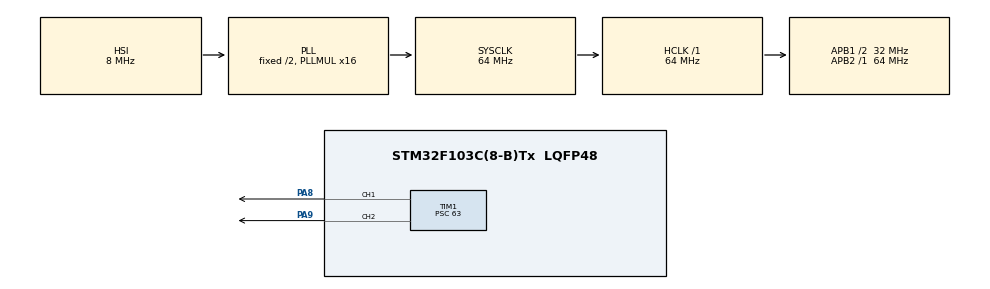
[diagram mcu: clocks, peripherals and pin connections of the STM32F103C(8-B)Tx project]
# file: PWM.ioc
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Mcu.Family=STM32F1
Mcu.Name=STM32F103C(8-B)Tx
Mcu.Package=LQFP48
NVIC.PriorityGroup=NVIC_PRIORITYGROUP_4
PA13.Mode=Serial_Wire
PA13.Signal=SYS_JTMS-SWDIO
PA14.Mode=Serial_Wire
PA14.Signal=SYS_JTCK-SWCLK
PA8.Signal=S_TIM1_CH1
PA9.Signal=S_TIM1_CH2
PD0-OSC_IN.Mode=HSE-External-Oscillator
PD0-OSC_IN.Signal=RCC_OSC_IN
PD1-OSC_OUT.Mode=HSE-External-Oscillator
PD1-OSC_OUT.Signal=RCC_OSC_OUT
ProjectManager.HeapSize=0x200
ProjectManager.StackSize=0x400
ProjectManager.TargetToolchain=MDK-ARM V5.32
RCC.AHBFreq_Value=64000000
RCC.APB1CLKDivider=RCC_HCLK_DIV2
RCC.APB1Freq_Value=32000000
RCC.APB1TimFreq_Value=64000000
RCC.APB2Freq_Value=64000000
RCC.APB2TimFreq_Value=64000000
RCC.HCLKFreq_Value=64000000
RCC.PLLMUL=RCC_PLL_MUL16
RCC.SYSCLKFreq_VALUE=64000000
RCC.SYSCLKSource=RCC_SYSCLKSOURCE_PLLCLK
RCC.USBFreq_Value=64000000
SH.S_TIM1_CH1.0=TIM1_CH1,PWM Generation1 CH1
SH.S_TIM1_CH2.0=TIM1_CH2,PWM Generation2 CH2
TIM1.Channel-PWM\ Generation1\ CH1=TIM_CHANNEL_1
TIM1.Channel-PWM\ Generation2\ CH2=TIM_CHANNEL_2
TIM1.Period=1999
TIM1.Prescaler=63
VP_TIM1_VS_ClockSourceINT.Mode=Internal
board=custom

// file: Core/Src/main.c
/* USER CODE BEGIN Header */
/**
  ******************************************************************************
  * @file           : main.c
  * @brief          : Main program body
  ******************************************************************************
  * @attention
  *
  * Copyright (c) 2023 STMicroelectronics.
  * All rights reserved.
  *
  * This software is licensed under terms that can be found in the LICENSE file
  * in the root directory of this software component.
  * If no LICENSE file comes with this software, it is provided AS-IS.
  *
  ******************************************************************************
  */
/* USER CODE END Header */
#include "main.h"

TIM_HandleTypeDef htim1;

void SystemClock_Config(void);
static void MX_GPIO_Init(void);
static void MX_TIM1_Init(void);
/* USER CODE BEGIN PFP */
void pwmSetDuty(TIM_HandleTypeDef *htim, uint32_t Channel, uint8_t duty)
{
	uint16_t ARR = __HAL_TIM_GetAutoreload(htim);	//htim -> Instance -> ARR
	uint16_t CCR = ARR*duty/100;
	__HAL_TIM_SetCompare(htim,Channel,1000);
}

/* USER CODE END PFP */

int main(void)
{

  /* MCU Configuration--------------------------------------------------------*/

  /* Reset of all peripherals, Initializes the Flash interface and the Systick. */
  HAL_Init();

  /* Configure the system clock */
  SystemClock_Config();

  /* Initialize all configured peripherals */
  MX_GPIO_Init();
  MX_TIM1_Init();
  /* USER CODE BEGIN 2 */
	HAL_TIM_PWM_Start(&htim1,TIM_CHANNEL_1);
	__HAL_TIM_SetCompare(&htim1,TIM_CHANNEL_1,1000);	//cach1
	//htim1.Instance -> CCR1 = 1000;									//cach2: thay doi gia tri trong thanh ghi CCR1
	//TIM1 -> CCR1 = 1000;														//cach 3: lap trinh bang thanh ghi

  /* USER CODE END 2 */

  /* Infinite loop */
  while (1)
  {

    /* USER CODE BEGIN 3 */
		for(uint8_t i=0; i<=100; i++)
		{
			pwmSetDuty(&htim1,TIM_CHANNEL_1,i);
			pwmSetDuty(&htim1,TIM_CHANNEL_2,100-i);
			HAL_Delay(10);
		}
  }
  /* USER CODE END 3 */
}

void SystemClock_Config(void)
{
  RCC_OscInitTypeDef RCC_OscInitStruct = {0};
  RCC_ClkInitTypeDef RCC_ClkInitStruct = {0};

  /** Initializes the RCC Oscillators according to the specified parameters
  * in the RCC_OscInitTypeDef structure.
  */
  RCC_OscInitStruct.OscillatorType = RCC_OSCILLATORTYPE_HSI;
  RCC_OscInitStruct.HSIState = RCC_HSI_ON;
  RCC_OscInitStruct.HSICalibrationValue = RCC_HSICALIBRATION_DEFAULT;
  RCC_OscInitStruct.PLL.PLLState = RCC_PLL_ON;
  RCC_OscInitStruct.PLL.PLLSource = RCC_PLLSOURCE_HSI_DIV2;
  RCC_OscInitStruct.PLL.PLLMUL = RCC_PLL_MUL16;
  if (HAL_RCC_OscConfig(&RCC_OscInitStruct) != HAL_OK)
  {
    Error_Handler();
  }

  /** Initializes the CPU, AHB and APB buses clocks
  */
  RCC_ClkInitStruct.ClockType = RCC_CLOCKTYPE_HCLK|RCC_CLOCKTYPE_SYSCLK
                              |RCC_CLOCKTYPE_PCLK1|RCC_CLOCKTYPE_PCLK2;
  RCC_ClkInitStruct.SYSCLKSource = RCC_SYSCLKSOURCE_PLLCLK;
  RCC_ClkInitStruct.AHBCLKDivider = RCC_SYSCLK_DIV1;
  RCC_ClkInitStruct.APB1CLKDivider = RCC_HCLK_DIV2;
  RCC_ClkInitStruct.APB2CLKDivider = RCC_HCLK_DIV1;

  if (HAL_RCC_ClockConfig(&RCC_ClkInitStruct, FLASH_LATENCY_2) != HAL_OK)
  {
    Error_Handler();
  }
}

static void MX_TIM1_Init(void)
{

  TIM_ClockConfigTypeDef sClockSourceConfig = {0};
  TIM_MasterConfigTypeDef sMasterConfig = {0};
  TIM_OC_InitTypeDef sConfigOC = {0};
  TIM_BreakDeadTimeConfigTypeDef sBreakDeadTimeConfig = {0};

  htim1.Instance = TIM1;
  htim1.Init.Prescaler = 63;
  htim1.Init.CounterMode = TIM_COUNTERMODE_UP;
  htim1.Init.Period = 1999;
  htim1.Init.ClockDivision = TIM_CLOCKDIVISION_DIV1;
  htim1.Init.RepetitionCounter = 0;
  htim1.Init.AutoReloadPreload = TIM_AUTORELOAD_PRELOAD_DISABLE;
  if (HAL_TIM_Base_Init(&htim1) != HAL_OK)
  {
    Error_Handler();
  }
  sClockSourceConfig.ClockSource = TIM_CLOCKSOURCE_INTERNAL;
  if (HAL_TIM_ConfigClockSource(&htim1, &sClockSourceConfig) != HAL_OK)
  {
    Error_Handler();
  }
  if (HAL_TIM_PWM_Init(&htim1) != HAL_OK)
  {
    Error_Handler();
  }
  sMasterConfig.MasterOutputTrigger = TIM_TRGO_RESET;
  sMasterConfig.MasterSlaveMode = TIM_MASTERSLAVEMODE_DISABLE;
  if (HAL_TIMEx_MasterConfigSynchronization(&htim1, &sMasterConfig) != HAL_OK)
  {
    Error_Handler();
  }
  sConfigOC.OCMode = TIM_OCMODE_PWM1;
  sConfigOC.Pulse = 0;
  sConfigOC.OCPolarity = TIM_OCPOLARITY_HIGH;
  sConfigOC.OCNPolarity = TIM_OCNPOLARITY_HIGH;
  sConfigOC.OCFastMode = TIM_OCFAST_DISABLE;
  sConfigOC.OCIdleState = TIM_OCIDLESTATE_RESET;
  sConfigOC.OCNIdleState = TIM_OCNIDLESTATE_RESET;
  if (HAL_TIM_PWM_ConfigChannel(&htim1, &sConfigOC, TIM_CHANNEL_1) != HAL_OK)
  {
    Error_Handler();
  }
  if (HAL_TIM_PWM_ConfigChannel(&htim1, &sConfigOC, TIM_CHANNEL_2) != HAL_OK)
  {
    Error_Handler();
  }
  sBreakDeadTimeConfig.OffStateRunMode = TIM_OSSR_DISABLE;
  sBreakDeadTimeConfig.OffStateIDLEMode = TIM_OSSI_DISABLE;
  sBreakDeadTimeConfig.LockLevel = TIM_LOCKLEVEL_OFF;
  sBreakDeadTimeConfig.DeadTime = 0;
  sBreakDeadTimeConfig.BreakState = TIM_BREAK_DISABLE;
  sBreakDeadTimeConfig.BreakPolarity = TIM_BREAKPOLARITY_HIGH;
  sBreakDeadTimeConfig.AutomaticOutput = TIM_AUTOMATICOUTPUT_DISABLE;
  if (HAL_TIMEx_ConfigBreakDeadTime(&htim1, &sBreakDeadTimeConfig) != HAL_OK)
  {
    Error_Handler();
  }
  HAL_TIM_MspPostInit(&htim1);

}

static void MX_GPIO_Init(void)
{

  /* GPIO Ports Clock Enable */
  __HAL_RCC_GPIOD_CLK_ENABLE();
  __HAL_RCC_GPIOA_CLK_ENABLE();

}

void Error_Handler(void)
{
  __disable_irq();
  while (1)
  {
  }
}
